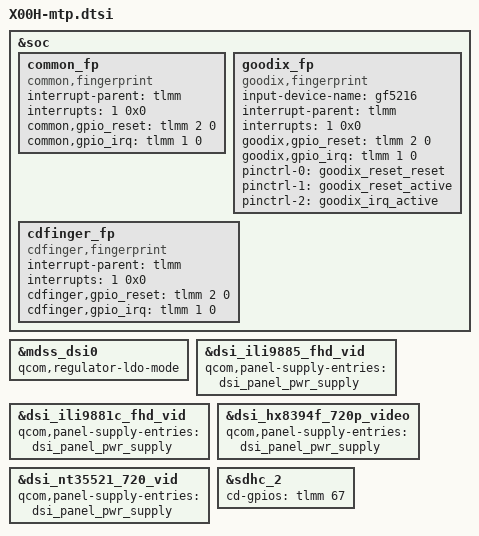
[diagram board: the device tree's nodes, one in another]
/*
 * Copyright (c) 2015-2018, The Linux Foundation. All rights reserved.
 *
 * This program is free software; you can redistribute it and/or modify
 * it under the terms of the GNU General Public License version 2 and
 * only version 2 as published by the Free Software Foundation.
 *
 * This program is distributed in the hope that it will be useful,
 * but WITHOUT ANY WARRANTY; without even the implied warranty of
 * MERCHANTABILITY or FITNESS FOR A PARTICULAR PURPOSE.  See the
 * GNU General Public License for more details.
 */

&soc {
	common_fp {
		compatible = "common,fingerprint";
		interrupt-parent = <&tlmm>;
		interrupts = <1 0x0>;

		common,gpio_reset    = <&tlmm 2 0>;
		common,gpio_irq      = <&tlmm 1 0>;
	};

	goodix_fp {
		compatible = "goodix,fingerprint";
		input-device-name = "gf5216";
		interrupt-parent = <&tlmm>;
		interrupts = <1 0x0>;

		goodix,gpio_reset    = <&tlmm 2 0>;
		goodix,gpio_irq      = <&tlmm 1 0>;

		pinctrl-names = "goodixfp_reset_reset",
				"goodixfp_reset_active",
				"goodixfp_irq_active";

		pinctrl-0 = <&goodix_reset_reset>;
		pinctrl-1 = <&goodix_reset_active>;
		pinctrl-2 = <&goodix_irq_active>;
	};

	cdfinger_fp {
		compatible = "cdfinger,fingerprint";
		interrupt-parent = <&tlmm>;
		interrupts = <1 0x0>;
		cdfinger,gpio_reset = <&tlmm 2 0>;
		cdfinger,gpio_irq = <&tlmm 1 0>;
	};
};

&mdss_dsi0 {
	qcom,regulator-ldo-mode;
};

&dsi_ili9885_fhd_vid {
	qcom,panel-supply-entries = <&dsi_panel_pwr_supply>;
};

&dsi_ili9881c_fhd_vid {
	qcom,panel-supply-entries = <&dsi_panel_pwr_supply>;
};

&dsi_hx8394f_720p_video {
	qcom,panel-supply-entries = <&dsi_panel_pwr_supply>;
};

&dsi_nt35521_720_vid {
	qcom,panel-supply-entries = <&dsi_panel_pwr_supply>;
};

&sdhc_2 {
	cd-gpios = <&tlmm 67 0x0>;
};
